# RFBI register map
Vendor: Texas Instruments
Peripheral module from a debugger description file (folder omap36xx).
Registers are 32-bit, read-write, reset 0x0 unless marked. A register's access mark holds for its fields unless they carry their own. Offsets are as the file gives them; lines under a group give offsets from that group; [hi:lo] are bit positions; {n}, {i} and the like mark numbered series; 'fields as' and 'values as' point back to an identical list; <NAME> marks a mode.

## RFBI
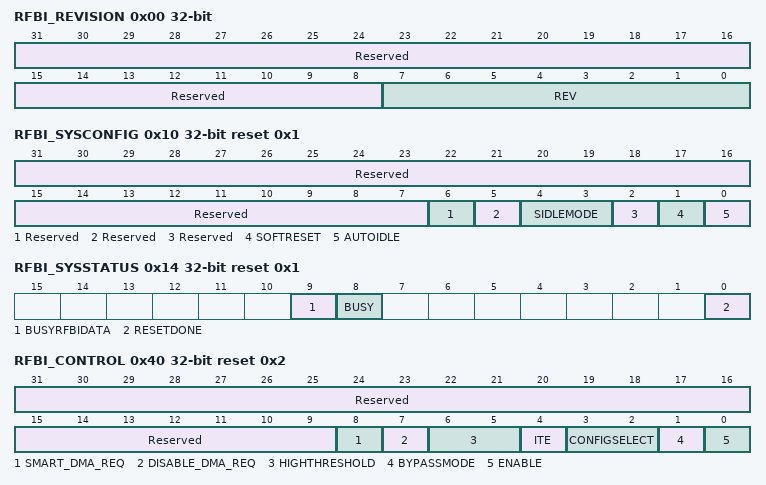
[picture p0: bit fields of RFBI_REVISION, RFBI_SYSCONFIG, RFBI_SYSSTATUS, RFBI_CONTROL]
0x00 RFBI_REVISION ro (reset mask 0xFFFFFF00) — This register contains the IP revision code.
  [31:8] Reserved — Read returns 0.
  [7:0] REV — IP revision[7:4] Major revision[3:0] Minor revision
0x10 RFBI_SYSCONFIG reset 0x1 — This register allows control of various parameters of the interconnect interface.
  [31:7] Reserved — Write 0s for future compatibility. Read returns 0.
  [6] Reserved — Write 0s for future compatibility. Read returns 0.
  [5] Reserved — Write 0s for future compatibility. Read returns 0.
  [4:3] SIDLEMODE — Slave interface power management, Idle req/ack control00: Force-idle: Idle request is acknowledged unconditionally.01: No idle: An idle request is never acknowledged10: Smart idle: Idle request is acknowledged based on the internal activity of the module.11: Reserved
  [2] Reserved — Write 0s for future compatibilityRead returns 0
  [1] SOFTRESET — Software resetSets this bit to 1 to trigger a module reset. The bit is automatically reset by the hardware. During reads, it always returns 0.0: Normal mode1: The module is reset
  [0] AUTOIDLE — Internal clock gating strategy (interconnectL4 and display controller clock)0: Interconnect L4 clock and display controller clock are free-running.1: Automatic clock gating strategy is applied for the interconnect L4 clock and display controller clock, based on the interconnect interface and internal activity.
0x14 RFBI_SYSSTATUS ro reset 0x1 — This register provides status information about the module, excluding the interrupt status information.
  [9] BUSYRFBIDATA — Data are pending to be processed from interconnect FIFO.Read 0x0: No data pending Read 0x1: Some data are pending
  [8] BUSY — L4 Interface busy status bitRead 0x0: The access to the following register is not stalled: RFBI_CMD, RFBI_DATA, RFBI_STATUS, RFBI_PARAM, RFBI_READ.Read 0x1: The access to any of the following registers is stalled: RFBI_CMD, RFBI_DATA, RFBI_STATUS, RFBI_PARAM, RFBI_READ.
  [0] RESETDONE — Internal reset monitoring0: Internal module reset is on-going1: Reset completed
0x40 RFBI_CONTROL reset 0x2 — The control register allows configuration of the RFBI module.
  [31:9] Reserved — Write 0s for future compatibilityRead returns 0
  [8] SMART_DMA_REQ — Smart DMA request
    0=The dmareq is asserted and de-asserted depending on the interconnect FIFO space even if MIdlereq is high in smart idle/no-idle mode and the entire burst gets error responses from the module; 1=The dmareq is de-asserted after 2 clk cycles if it has been asserted for more than or equal to 2 clk cycles and MIdlereq is high in smart idle or no idle mode. No more burst requests will be given even if the space is available in the interconnect FIFO.
  [7] DISABLE_DMA_REQ — Disable DMA request
    0=The dmareq is enabled and the signal is generated based on the space available and the request coming into the data register; 1=The dmareq is disabled and the signal is not generated at all based on space in the interconnect FIFO. It stays high until the DISABLE DMAREQ is high even if there is space in the interconnect FIFO to take requests.
  [6:5] HIGHTHRESHOLD — Defines the interconnect FIFO high threshold used by HW to assert DMA request. Used only if data written toRFBI_DATA are sent using system DMA.
    0=Size of the transfer of 4 words of 32-bit wide; 1=Size of the transfer of 8 words of 32-bit wide; 2=Size of the transfer of 16 words of 32-bit wide
  [4] ITE — Internal Trigger0: H/W waits for ITE bit to be set if in internal trigger mode for the configuration in use.1: User sets the ITE bit to start the transfer, when H/W takes into account the bit, the H/W resets it.
  [3:2] CONFIGSELECT — Select the CS and configuration00: No CS selected01: CS0 selected and configuration #010: CS1 selected and configuration #111: CS0 and CS1 both selected (only the configuration for CS0 is used)
  [1] BYPASSMODE — Bypass Mode0: The bypass mode not selected1: The bypass mode is selected
  [0] ENABLE — Enable/Disable flag0: Disable the RFBI module1: Enable the RFBI module
0x44 RFBI_PIXEL_CNT — The control register configures the RFBI pixel count value.
  [31:0] PIXELCNT — Pixel counter valueThe S/W indicates the number of pixels to transfer to the LCD panel frame buffer. The value is set when the module is disabled. During the transfer the HW decrements the register when a pixel has been sent to the RFB.
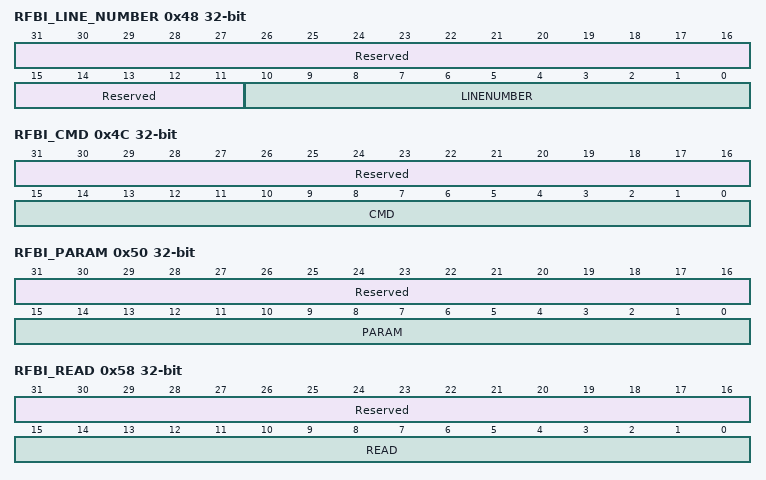
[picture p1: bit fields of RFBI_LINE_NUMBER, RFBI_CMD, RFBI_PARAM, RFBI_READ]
0x48 RFBI_LINE_NUMBER — The control register configures the number of lines to synchronize the beginning of the transfer.
  [31:11] Reserved — Write 0s for future compatibilityRead returns 0
  [10:0] LINENUMBER — Programmable line numberLine number from 0 to 2-1. Number of HSYNC after the VSYNC occurs before the beginning of the transfer.
0x4C RFBI_CMD wo — The control register configures the RFBI command
  [31:16] Reserved — Write 0s for future compatibilityRead returns 0
  [15:0] CMD — Command Value8/9/12/16 bit value depending on the parallel mode[7:0] 8-bit DT[8:0] 9-bit Data type[11:0] 12-bit Data type[15:0] 16-bit Data type
0x50 RFBI_PARAM wo — The control register configures the RFBI parameter.
  [31:16] Reserved — Write 0s for future compatibilityRead returns 0
  [15:0] PARAM — Param Value8/9/12/16 bit value depending on the parallel mode[7:0] 8-bit Data type[8:0] 9-bit Data type[11:0] 12-bit Data type[15:0] 16-bit Data type
0x54 RFBI_DATA wo — The control register configures the RFBI data.
  [31:0] DATA — Data value12/16/18/24/2x16 bit value depending on the Data type[11:0] 12-bit Data type[15:0] 16-bit Data type[17:0] 18-bit Data type[23:0] 24-bit Data type[31:0] 2x16-bit Data type
0x58 RFBI_READ — The control register configures the RFBI read
  [31:16] Reserved — Write 0s for future compatibilityRead returns 0
  [15:0] READ — Read Value8/9/12/16 bit value depending on the parallel mode[7:0] 8-bit Data type[8:0] 9-bit Data type[11:0] 12-bit Data type[15:0] 16-bit Data type
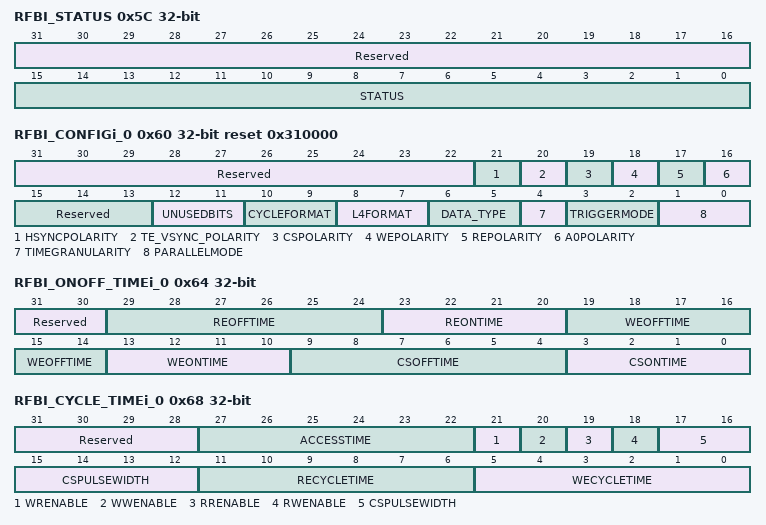
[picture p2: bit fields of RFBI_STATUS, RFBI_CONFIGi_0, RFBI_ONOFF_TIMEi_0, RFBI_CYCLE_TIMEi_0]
0x5C RFBI_STATUS — The control register configures the RFBI status.
  [31:16] Reserved — Write 0s for future compatibilityRead returns 0
  [15:0] STATUS — Status value8/9/12/16 bit value depending on the parallel mode[7:0] 8-bit Data type[8:0] 9-bit Data type[11:0] 12-bit Data type[15:0] 16-bit Data type
0x60 RFBI_CONFIGi_0 reset 0x310000 — The control register allows configuration #I of the RFBI module.
  [31:22] Reserved — Write 0s for future compatibilityRead returns 0
  [21] HSYNCPOLARITY — HSYNC polarity0: HSYNC active low1: HSYNC active high
  [20] TE_VSYNC_POLARITY — TE or VSYNC Polarity0: TE or VSYNC active low1: TE or SYNC active high
  [19] CSPOLARITY — CS Polarity0: CS active low defined at reset time1: CS active high defined at reset time
  [18] WEPOLARITY — WE Polarity0: WE active low1: WE active high
  [17] REPOLARITY — RE Polarity0: RE active low1: RE active high
  [16] A0POLARITY — A0 Polarity0: A0 active low1: A0 active high
  [15:13] Reserved — Write 0s for future compatibilityRead returns 0
  [12:11] UNUSEDBITS — State of unused bits00: Low level (0)01: High level (1)10: Unchanged from previous state11: Reserved
  [10:9] CYCLEFORMAT — Cycle format00: 1 cycle for 1 pixel01: 2 cycles for 1 pixel10: 3 cycles for 1 pixel11: 3 cycles for 2 pixels
  [8:7] L4FORMAT — L4 Write Access format00: 1 pixel per L4 access to the register data01: Reserved10: 2 pixels per L4 access to the register data with 1st pixel at the position [15:0]11: 2 pixels per L4 access to the register data with 1st pixel at the position [31:16]
  [6:5] DATA_TYPE — Data type from the display controller and L400: 12-bit01: 16-bit10: 18-bit11: 24-bit
  [4] TIMEGRANULARITY — Multiplies signal timing latencies by two0: x2 latencies disabled1: x2 latencies enabled
  [3:2] TRIGGERMODE — Trigger Mode00: Internal trigger mode (ITE bit mode)01: External trigger mode (TE signal)10: External trigger mode (VSYNC/HSYNC signals)11: Reserved
  [1:0] PARALLELMODE — Parallel Mode00: 8-bit parallel output interface selected01: 9-bit parallel output interface selected10: 12-bit parallel output interface selected11: 16-bit parallel output interface selected
0x64 RFBI_ONOFF_TIMEi_0 — The control register allows configuration of the RFBI timing.
  [31:30] Reserved — Write 0s for future compatibility.Read returns 0.
  [29:24] REOFFTIME — Read Enable deassertion time from start access timeNumber of L4Clk cycles
  [23:20] REONTIME — Read Enable assertion time from start access timeNumber of L4Clk cycles
  [19:14] WEOFFTIME — Write Enable deassertion time from start access timeNumber of L4Clk cycles
  [13:10] WEONTIME — Write Enable assertion time from start access timeNumber of L4Clk cycles
  [9:4] CSOFFTIME — CS deassertion time from start access timeNumber of L4Clk cycles
  [3:0] CSONTIME — CS assertion time from start access timeNumber of L4Clk cycles
0x68 RFBI_CYCLE_TIMEi_0 — The control register allows configuration of the RFBI timing.
  [31:28] Reserved — Write 0s for future compatibilityRead returns 0
  [27:22] ACCESSTIME — Access TimeNumber of L4Clk cycles
  [21] WRENABLE — Write to Read Pulse Width Enable (same CS)0: CSPulseWidth does not apply on Write to Read access1: CSPulseWidth applies on Write to Read access
  [20] WWENABLE — Write to Write Pulse Width Enable (same CS)0: CSPulseWidth does not apply on Write to Write access1: CSPulseWidth applies on Write to Write access
  [19] RRENABLE — Read to Read Pulse Width Enable (same CS)0: CSPulseWidth does not apply on Read to Read access1: CSPulseWidth applies on Read to Read access
  [18] RWENABLE — Read to Write Pulse Width Enable (same CS)0: CSPulseWidth does not apply on Read to Write access1: CSPulseWidth applies on Read to Write access
  [17:12] CSPULSEWIDTH — CS Pulse WidthNumber of L4Clk cycles
  [11:6] RECYCLETIME — RE Cycle TimeNumber of L4Clk cycles
  [5:0] WECYCLETIME — WE Cycle TimeNumber of L4Clk cycles
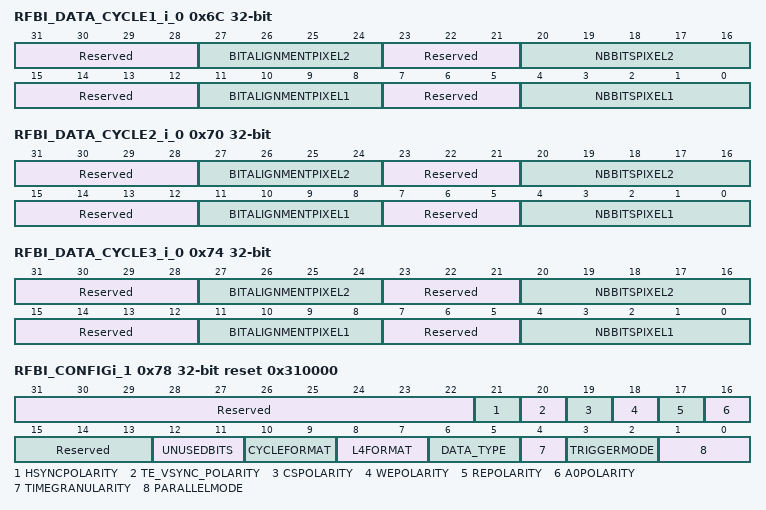
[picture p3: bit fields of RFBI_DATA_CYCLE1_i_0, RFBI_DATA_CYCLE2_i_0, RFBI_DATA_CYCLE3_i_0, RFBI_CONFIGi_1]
0x6C RFBI_DATA_CYCLE1_i_0 — The control register configures the RFBI data format for 1st cycle.
  [31:28] Reserved — Write 0s for future compatibilityRead returns 0
  [27:24] BITALIGNMENTPIXEL2 — Bit alignmentAlignment of the bits from pixel#2 on the output interface
  [23:21] Reserved — Write 0s for future compatibilityRead returns 0
  [20:16] NBBITSPIXEL2 — Number of bitsNumber of bits from the pixel #2 (value from 0 to16 bits). The values from 17 to 31 are invalid.
  [15:12] Reserved — Write 0s for future compatibilityRead returns 0
  [11:8] BITALIGNMENTPIXEL1 — Bit alignmentAlignment of the bits from pixel#1 on the output interface
  [7:5] Reserved — Write 0s for future compatibilityRead returns 0
  [4:0] NBBITSPIXEL1 — Number of bitsNumber of bits from the pixel #1 (value from 0 to16 bits). The values from 17 to 31 are invalid.
0x70 RFBI_DATA_CYCLE2_i_0 — The control register configures the RFBI data format for 2nd cycle.
  fields as RFBI_DATA_CYCLE1_i_0
0x74 RFBI_DATA_CYCLE3_i_0 — The control register configures the RFBI data format for 3rd cycle.
  fields as RFBI_DATA_CYCLE1_i_0
0x78 RFBI_CONFIGi_1 reset 0x310000 — The control register allows configuration #I of the RFBI module.
  fields as RFBI_CONFIGi_0
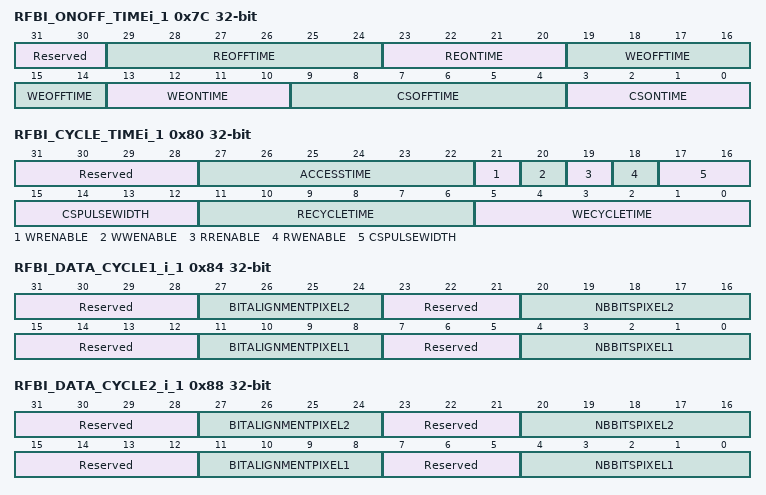
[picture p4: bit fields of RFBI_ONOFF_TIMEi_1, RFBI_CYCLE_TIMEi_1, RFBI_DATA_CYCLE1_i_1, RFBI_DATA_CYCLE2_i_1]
0x7C RFBI_ONOFF_TIMEi_1 — The control register allows configuration of the RFBI timing.
  fields as RFBI_ONOFF_TIMEi_0
0x80 RFBI_CYCLE_TIMEi_1 — The control register allows configuration of the RFBI timing.
  fields as RFBI_CYCLE_TIMEi_0
0x84 RFBI_DATA_CYCLE1_i_1 — The control register configures the RFBI data format for 1st cycle.
  fields as RFBI_DATA_CYCLE1_i_0
0x88 RFBI_DATA_CYCLE2_i_1 — The control register configures the RFBI data format for 2nd cycle.
  fields as RFBI_DATA_CYCLE1_i_0
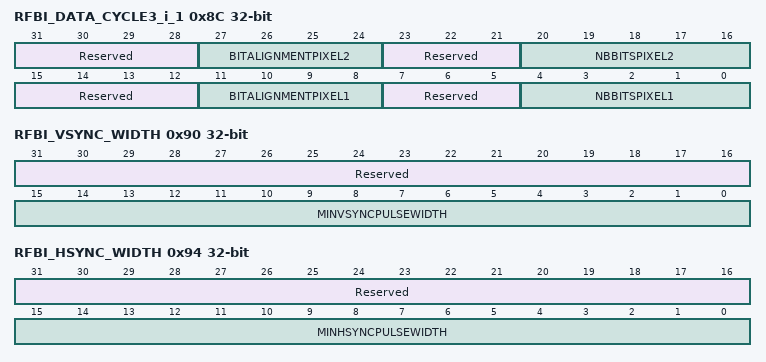
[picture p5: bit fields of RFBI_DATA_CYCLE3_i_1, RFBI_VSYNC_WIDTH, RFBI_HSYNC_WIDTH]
0x8C RFBI_DATA_CYCLE3_i_1 — The control register configures the RFBI data format for 3rd cycle.
  fields as RFBI_DATA_CYCLE1_i_0
0x90 RFBI_VSYNC_WIDTH — The control register configures the RFBI VSYNC minimum pulse width
  [31:16] Reserved — Write 0s for future compatibilityRead returns 0
  [15:0] MINVSYNCPULSEWIDTH — Programmable min VSYNC pulse widthMinimum VSYNC pulse width from 0 to 65535. Number of L4 clock cycles to determine when VSYNC pulse occurs. The values 0 and 1 are invalid.
0x94 RFBI_HSYNC_WIDTH — The control register configures the RFBI HSYNC minimum pulse width.
  [31:16] Reserved — Write 0s for future compatibilityRead returns 0
  [15:0] MINHSYNCPULSEWIDTH — Programmable min HSYNC pulse widthMinimum HSYNC pulse width from 0 to 65535. Number of L4 clock cycles to determine when HSYNC pulse occurs. The values 0 and 1 are invalid.
